AUTOSAR XML (schema 4-3-1)
package /Component
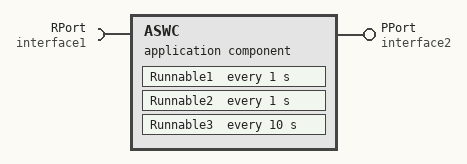
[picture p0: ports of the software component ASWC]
  application sw component type ASWC
    provide port PPort: provided-interface=interface2
      provided-com-specs:
        data-element=DE_{1..4}, init-value=0
    require port RPort: required-com-specs=[{data-element=DE1, init-value=0}, {data-element=DE1, init-value=0}, {data-element=DE2, init-value=0}], required-interface=interface1
    behavior test_IB: handle-termination-and-restart=NO-SUPPORT
      timing event Event_Runnable1: start-on-event=Runnable1, period=1
      timing event EventRunnalble3: start-on-event=Runnable2, period=1
      timing event EventRunnable3: start-on-event=Runnable3, period=10
      implicit-inter-runnable-variables:
        4 x data, all with category=VALUE, sw-calibration-access=READ-ONLY, type=Double:
          IRV{1..4}
      4 x runnable:
        Runnable_Init
        Runnable1
          data-read-access:
            access IN_RPort_DE1: accessed-variable=RPort.DE1
            access IN_RPort_DE1: accessed-variable=RPort.DE1
          data-write-access:
            access OUT_PPort_DE_1: accessed-variable=PPort.DE_1
          read-local-variables:
            access RV_IRV3: accessed-variable=IRV3
          written-local-variables:
            access WV_IRV1: accessed-variable=IRV1
        Runnable2
          data-write-access:
            access OUT_PPort_DE_3: accessed-variable=PPort.DE_3
            access OUT_PPort_DE_4: accessed-variable=PPort.DE_4
          read-local-variables:
            access RV_IRV1: accessed-variable=IRV1
            access RV_IRV2: accessed-variable=IRV2
          written-local-variables:
            access WV_IRV4: accessed-variable=IRV4
        Runnable3
          data-read-access:
            access IN_RPort_DE2: accessed-variable=RPort.DE2
          data-write-access:
            access OUT_PPort_DE_2: accessed-variable=PPort.DE_2
          read-local-variables:
            access RV_IRV4: accessed-variable=IRV4
          written-local-variables:
            access WV_IRV2: accessed-variable=IRV2
            access WV_IRV3: accessed-variable=IRV3
